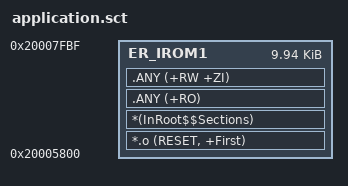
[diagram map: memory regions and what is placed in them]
; *************************************************************
; *** Scatter-Loading Description File generated by uVision ***
; *************************************************************

LR_IROM1 0x20005800 0x000027C0  {    ; load region size_region
  ER_IROM1 0x20005800 0x000027C0  {  ; load address = execution address
   *.o (RESET, +First)
   *(InRoot$$Sections)
   .ANY (+RO)
   .ANY (+RW +ZI)
  }
}
